# NSS_0_CFG_CPSW register map
Vendor: Texas Instruments
Peripheral module from a debugger description file (folder 66AK2G0x_66AK2G1x).
Registers are 32-bit, access per field, reset 0x0 unless marked. A register's access mark holds for its fields unless they carry their own. Offsets are as the file gives them; lines under a group give offsets from that group; [hi:lo] are bit positions; {n}, {i} and the like mark numbered series; 'fields as' and 'values as' point back to an identical list; <NAME> marks a mode.

## NSS_0_CFG_CPSW
0x00 CPSW_IDVER ro reset 0x4EE71100
  [31:0] REV — TI internal data. Identifies revision of peripheral.
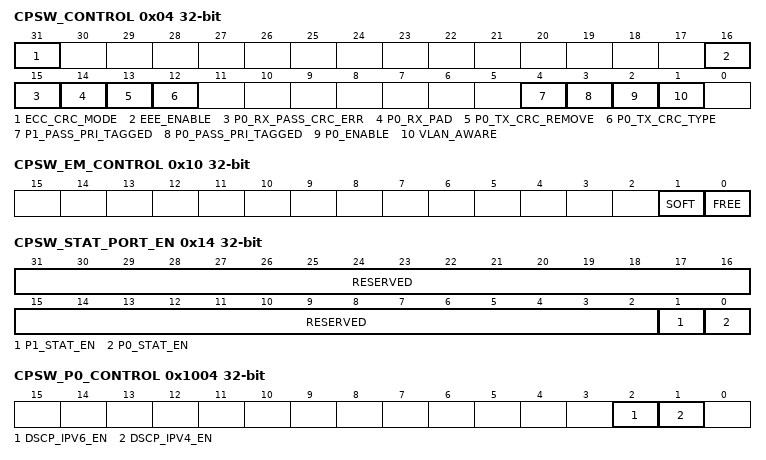
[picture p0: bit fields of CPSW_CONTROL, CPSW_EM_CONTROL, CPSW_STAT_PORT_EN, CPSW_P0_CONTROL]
0x04 CPSW_CONTROL
  [31] ECC_CRC_MODE rw
  [16] EEE_ENABLE rw — Energy Efficient Ethernet enable
  [15] P0_RX_PASS_CRC_ERR rw — Port 0 Pass Received CRC errors
  [14] P0_RX_PAD rw — Port 0 Receive Short Packet Pad
  [13] P0_TX_CRC_REMOVE rw — Port 0 Transmit CRC remove
  [12] P0_TX_CRC_TYPE rw — Port 0 Transmit CRC Type – The type of CRC on all Port 0 transmit packet (egress), regardless of the CRC type of in ingress Ethernet port.
  [4] P1_PASS_PRI_TAGGED rw — Port 1 Pass Priority Tagged
  [3] P0_PASS_PRI_TAGGED rw — Port 0 Pass Priority Tagged
  [2] P0_ENABLE rw — Port 0 Enable
  [1] VLAN_AWARE rw — VLAN Aware Mode
0x10 CPSW_EM_CONTROL
  [1] SOFT rw — Emulation Soft Bit
  [0] FREE rw — Emulation Free Bit
0x14 CPSW_STAT_PORT_EN
  [31:2] RESERVED ro — Reads return 0 and writes have no effect.
  [1] P1_STAT_EN rw — Port 1 Statistics Enable
  [0] P0_STAT_EN rw — Port 0 Statistics Enable
0x1C CPSW_SOFT_IDLE
  [0] SOFT_IDLE rw — Software Idle
0x2C CPSW_EEE_PRESCALE
  [11:0] EEE_PRESCALE rw — Energy Efficient Ethernet Pre-scale count load value - This value is loaded into the EEE pre-scale counter each time the pre-scale count decrements to zero. The EEE counters are enabled to decrement each time the pre-scale counter reaches zero (and the EEE counters are enabled to count time). If this value is zero then the EEE counters decrement on every clock. If this value is 0x001 then the counters decrement on every other clock (and so on).
0x1004 CPSW_P0_CONTROL
  [2] DSCP_IPV6_EN rw — Port 0 IPv6 DSCP enable
  [1] DSCP_IPV4_EN rw — Port 0 IPv4 DSCP enable
0x1008 CPSW_P0_FLOW_ID_OFFSET
  [7:0] FLOW_ID_OFFSET rw — This value is added to the thread/Flow_ID in CPPI transmit PSI Info Word 0
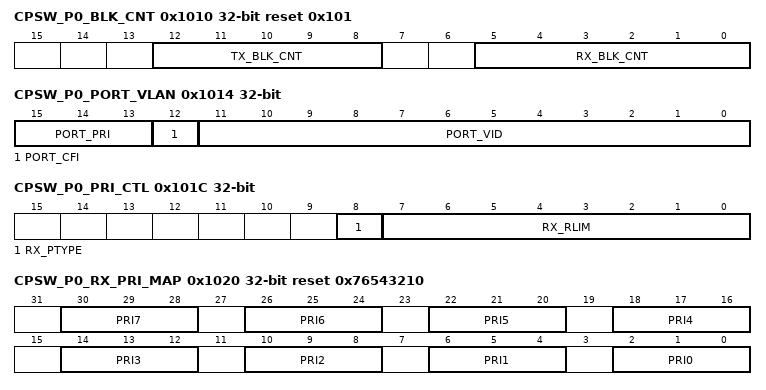
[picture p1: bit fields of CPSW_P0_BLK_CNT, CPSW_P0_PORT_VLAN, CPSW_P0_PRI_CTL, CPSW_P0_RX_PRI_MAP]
0x1010 CPSW_P0_BLK_CNT ro reset 0x101
  [12:8] TX_BLK_CNT — Port 0 Transmit Block Count Usage – This value is the number of blocks allocated to the FIFO logical transmit queues.
  [5:0] RX_BLK_CNT — Port 0 Receive Block Count Usage – This value is the number of blocks allocated in the receive FIFO.
0x1014 CPSW_P0_PORT_VLAN
  [15:13] PORT_PRI rw — Port VLAN Priority
  [12] PORT_CFI rw — Port CFI bit
  [11:0] PORT_VID rw — Port VLAN ID
0x101C CPSW_P0_PRI_CTL
  [8] RX_PTYPE rw — Receive Priority Type
  [7:0] RX_RLIM rw — Receive Rate Limit Enable
0x1020 CPSW_P0_RX_PRI_MAP reset 0x76543210
  [4n+2:4n] PRI{n} rw (n=0..7) — Priority {n} – A packet pri of {0x0+n} is mapped (changed) to this header packet pri.
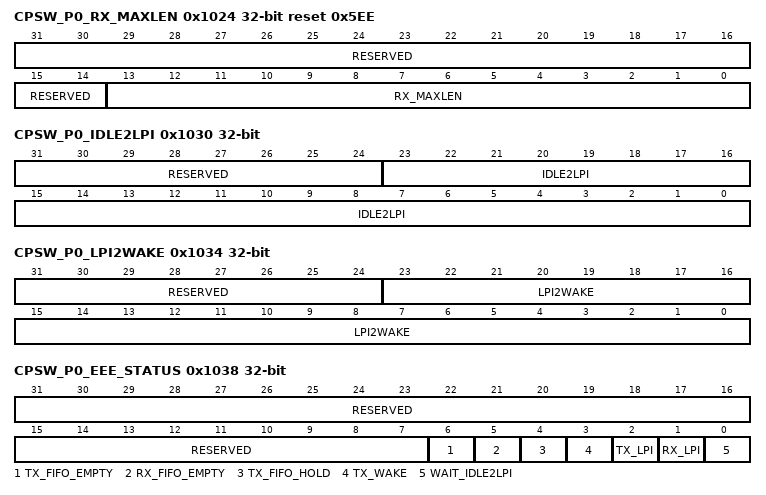
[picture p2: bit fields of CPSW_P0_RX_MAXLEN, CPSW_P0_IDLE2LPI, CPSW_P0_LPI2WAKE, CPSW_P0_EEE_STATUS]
0x1024 CPSW_P0_RX_MAXLEN reset 0x5EE
  [31:14] RESERVED ro — Reads return 0 and writes have no effect.
  [13:0] RX_MAXLEN rw — Rx Maximum Frame Length – This field determines the maximum length of a received frame. The reset value is 1518 (dec). Frames with byte counts greater than RX_MAXLEN are long frames. Long frames with no errors are oversized frames. Long frames with CRC, code, or alignment error are jabber frames. The maximum value is 2020 (including VLAN).
0x1030 CPSW_P0_IDLE2LPI
  [31:24] RESERVED ro — Reads return 0 and writes have no effect.
  [23:0] IDLE2LPI rw — Port 0 EEE Idle to LPI counter load value - After EEE_CLKSTOP_REQ is asserted, this value is loaded into the port 0 idle to LPI counter on each clock that the port 0 transmit or receive is not idle. Port 0 enters the LPI state when this count decrements to zero (on the prescale count). This count value should be large relative to switch operations.
0x1034 CPSW_P0_LPI2WAKE
  [31:24] RESERVED ro — Reads return 0 and writes have no effect.
  [23:0] LPI2WAKE rw — Port 0 EEE LPI to wake counter load value – When the port is in the transmit LPI state and the EEE_CLKSTOP_REQ signal is deasserted, this value is loaded into the port 0 LPI to wake counter. Transmit and receive packet operations may begin (resume) when the LPI to wake count decrements to zero (on the prescale count). This is the time waited before CPPI packet operations begin (resume after wakeup). This count value should be large relative to switch operations.
0x1038 CPSW_P0_EEE_STATUS ro
  [31:7] RESERVED — Reads return 0 and writes have no effect.
  [6] TX_FIFO_EMPTY — CPPI port 0 transmit FIFO (switch egress) is empty - contains no packets
  [5] RX_FIFO_EMPTY — CPPI port 0 receive FIFO (switch ingress) is empty - contains no packets
  [4] TX_FIFO_HOLD — CPPI port 0 transmit FIFO hold - asserted in the LPI state and during the LPI2WAKE count time
  [3] TX_WAKE — CPPI port 0 transmit wakeup - asserted in the transmit LPI2WAKE count time
  [2] TX_LPI — CPPI port 0 transmit LPI state - asserted when the port 0 transmit is in the LPI state
  [1] RX_LPI — CPPI port 0 receive LPI state - asserted when the port 0 receive is in the LPI state
  [0] WAIT_IDLE2LPI — CPPI port 0 wait idle to LPI - asserted when port 0 is counting the IDLE2LPI time
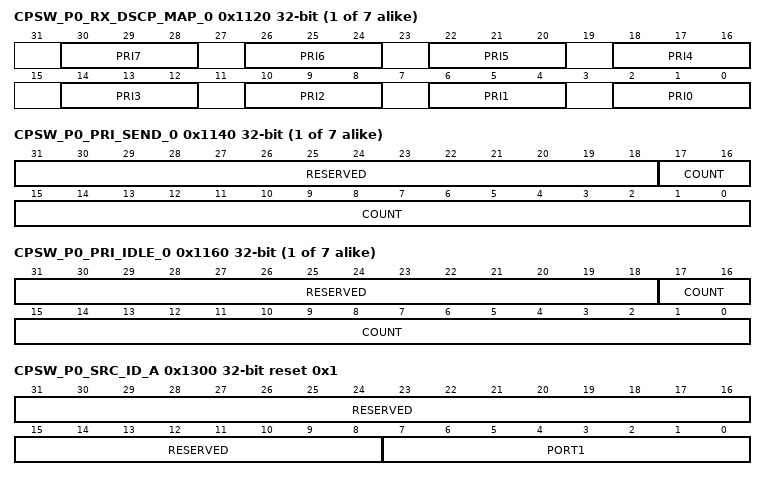
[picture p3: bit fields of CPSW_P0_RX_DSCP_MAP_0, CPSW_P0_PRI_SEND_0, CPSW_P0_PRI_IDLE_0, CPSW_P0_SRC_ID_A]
{0x1120+4i} CPSW_P0_RX_DSCP_MAP_{i} (i=0..6)
  [4n+2:4n] PRI{n} rw (n=0..7) — A DSCP IPV4/V6 packet TOS of N*8+{n} is mapped to this received priority, where N = 0 to 7
{0x1140+4i} CPSW_P0_PRI_SEND_{i} (i=0..6)
  [31:18] RESERVED ro — Reads return 0 and writes have no effect.
  [17:0] COUNT rw — Priority N send count, where N = 0 to 7
{0x1160+4i} CPSW_P0_PRI_IDLE_{i} (i=0..6)
  [31:18] RESERVED ro — Reads return 0 and writes have no effect.
  [17:0] COUNT rw — Priority N idle count, where N = 0 to 7
0x1300 CPSW_P0_SRC_ID_A reset 0x1
  [31:8] RESERVED ro — Reads return 0 and writes have no effect.
  [7:0] PORT1 rw — Port 1 CPPI Info Word0 Source ID Value. This value is contained in the CPPI Info Word 0 src_id field for packets received on port 1.
0x2000 CPSW_P1_RESERVED ro
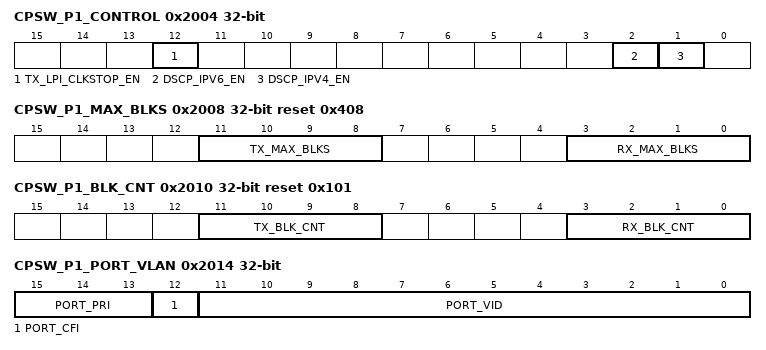
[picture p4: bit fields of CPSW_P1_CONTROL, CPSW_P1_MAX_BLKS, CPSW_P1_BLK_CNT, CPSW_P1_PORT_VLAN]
0x2004 CPSW_P1_CONTROL
  [12] TX_LPI_CLKSTOP_EN rw — Transmit LPI clockstop enable
  [2] DSCP_IPV6_EN rw — IPv6 DSCP enable
  [1] DSCP_IPV4_EN rw — IPv4 DSCP enable
0x2008 CPSW_P1_MAX_BLKS ro reset 0x408
  [11:8] TX_MAX_BLKS — Transmit FIFO maximum blocks - This value is the maximum number of 1k memory blocks that may be allocated to the FIFO’s logical transmit priority queues. The recommended value of TX_MAX_BLKS is 0x4.
  [3:0] RX_MAX_BLKS — Receive FIFO maximum blocks – This value is the maximum number of 1k memory blocks that may be allocated to the FIFO’s logical receive queue. This value must be greater than or equal to 0x3. The recommended value of RX_MAX_BLKS is 0x8.
0x2010 CPSW_P1_BLK_CNT ro reset 0x101
  [11:8] TX_BLK_CNT — Transmit Block Count Usage – This value is the number of blocks allocated to the port’s FIFO logical transmit queues.
  [3:0] RX_BLK_CNT — Receive Block Count Usage – This value is the number of blocks allocated to the port’s FIFO receive queue.
0x2014 CPSW_P1_PORT_VLAN
  [15:13] PORT_PRI rw — Port VLAN Priority (7 is highest priority)
  [12] PORT_CFI rw — Port CFI bit
  [11:0] PORT_VID rw — Port VLAN ID
0x201C CPSW_P1_PRI_CTL reset 0x9000
  [15:12] TX_HOST_BLKS_REM rw — Transmit FIFO Blocks that must be free before a non rate-limited CPPI Port 0 receive thread can begin sending a packet
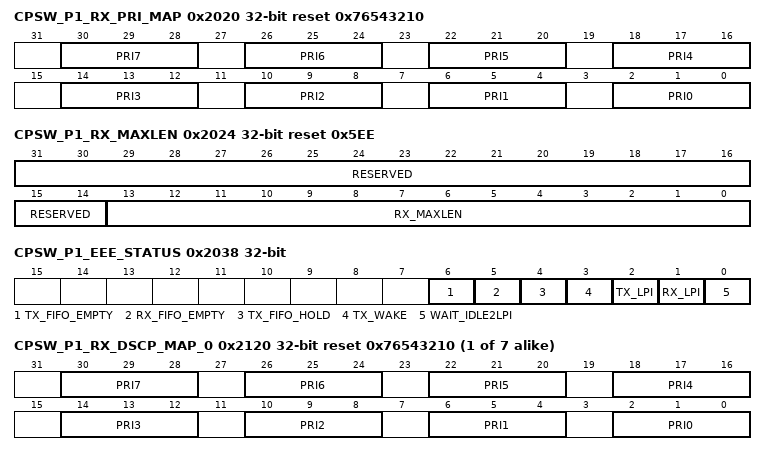
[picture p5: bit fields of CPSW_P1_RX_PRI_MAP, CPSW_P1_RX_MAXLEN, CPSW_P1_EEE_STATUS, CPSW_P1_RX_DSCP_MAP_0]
0x2020 CPSW_P1_RX_PRI_MAP reset 0x76543210
  fields as CPSW_P0_RX_PRI_MAP
0x2024 CPSW_P1_RX_MAXLEN reset 0x5EE
  [31:14] RESERVED ro — Reads return 0 and writes have no effect.
  [13:0] RX_MAXLEN rw — Rx Maximum Frame Length – This field determines the maximum length of a received frame. The reset value is 1518 (dec). Frames with byte counts greater than RX_MAXLEN are long frames. Long frames with no errors are oversized frames. Long frames with CRC, code, or alignment error are jabber frames. The maximum value is 9604 (including VLAN).
0x2030 CPSW_P1_IDLE2LPI
  [23:0] IDLE2LPI rw — EEE Idle to LPI counter load value- After EEE_CLKSTOP_REQ is asserted, this value is loaded into the port idle to LPI counter on each clock that the port transmit is not idle. The port enters the transmit LPI state when this count decrements to zero. This count decrements each time the EEE prescale count decrements to zero.
0x2034 CPSW_P1_LPI2WAKE
  [23:0] LPI2WAKE rw — EEE LPI to wake counter load value – When the port is in the transmit LPI state and the EEE_CLKSTOP_REQ signal is deasserted, this value is loaded into the LPI to wake counter. Transmit packet operations may begin (resume) when the LPI to wake count decrements to zero (on the pre-scale count). This is the time waited before Ethernet transmit operations resume after wakeup.
0x2038 CPSW_P1_EEE_STATUS ro
  [6] TX_FIFO_EMPTY — Transmit FIFO (switch egress) is empty - contains no packets
  [5] RX_FIFO_EMPTY — Receive FIFO (switch ingress) is empty - contains no packets
  [4] TX_FIFO_HOLD — Transmit FIFO hold - asserted in the LPI state and during the LPI2WAKE count time
  [3] TX_WAKE — Transmit wakeup - asserted in the transmit LPI2WAKE count time
  [2] TX_LPI — Transmit LPI state - asserted when the port 0 transmit is in the LPI state
  [1] RX_LPI — Receive LPI state - asserted when the port 0 receive is in the LPI state
  [0] WAIT_IDLE2LPI — CPPI port 0 wait idle to LPI - asserted when port 0 is counting the IDLE2LPI time
{0x2120+4i} CPSW_P1_RX_DSCP_MAP_{i} reset 0x76543210 (i=0..6)
  [4n+2:4n] PRI{n} rw (n=0..7) — A DSCP IPV4/V6 packet TOS of N*8+{n} is mapped to this received priority, where N = 0 to 7.
{0x2140+4i} CPSW_P1_PRI_SEND_{i} (i=0..6)
  [17:0] COUNT rw — Priority N send count, where N = 0 to 7.
{0x2160+4i} CPSW_P1_PRI_IDLE_{i} (i=0..6)
  [17:0] COUNT rw — Priority N idle count, where N = 0 to 7
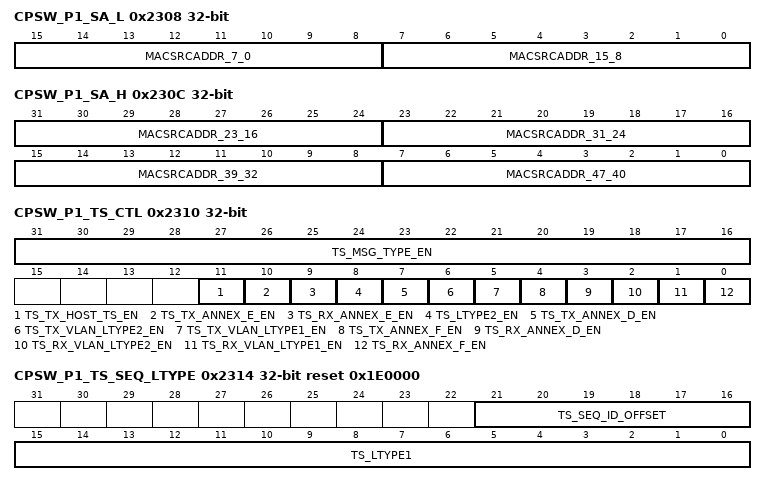
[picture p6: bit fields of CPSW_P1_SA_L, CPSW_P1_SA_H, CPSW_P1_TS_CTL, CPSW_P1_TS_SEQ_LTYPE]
0x2308 CPSW_P1_SA_L
  [15:8] MACSRCADDR_7_0 rw — Source Address Lower 8 bits (byte 0)
  [7:0] MACSRCADDR_15_8 rw — Source Address bits 15:8 (byte 1)
0x230C CPSW_P1_SA_H rw
  [31:24] MACSRCADDR_23_16 — Source Address bits 23:16 (byte 2)
  [23:16] MACSRCADDR_31_24 — Source Address bits 31:24 (byte 3)
  [15:8] MACSRCADDR_39_32 — Source Address bits 39:32 (byte 4)
  [7:0] MACSRCADDR_47_40 — Source Address bits 47:40 (byte 5)
0x2310 CPSW_P1_TS_CTL
  [31:16] TS_MSG_TYPE_EN rw — Time Sync Message Type Enable Each bit in this field enables the corresponding message type in receive and transmit time sync messages (Bit 0 enables message type 0, etc.).
  [11] TS_TX_HOST_TS_EN rw — Time Sync Transmit Host Time Stamp Enable
  [10] TS_TX_ANNEX_E_EN rw — Time Sync Transmit Annex E Enable
  [9] TS_RX_ANNEX_E_EN rw — Time Sync Receive Annex E Enable
  [8] TS_LTYPE2_EN rw — Time Sync LTYPE 2 enable (Transmit and Receive)
  [7] TS_TX_ANNEX_D_EN rw — Time Sync Transmit Annex D Enable
  [6] TS_TX_VLAN_LTYPE2_EN rw — Time Sync Transmit VLAN LTYPE 2 enable
  [5] TS_TX_VLAN_LTYPE1_EN rw — Time Sync Transmit VLAN LTYPE 1 enable
  [4] TS_TX_ANNEX_F_EN rw — Time Sync Transmit Annex F Enable
  [3] TS_RX_ANNEX_D_EN rw — Time Sync Receive Annex D Enable
  [2] TS_RX_VLAN_LTYPE2_EN rw — Time Sync Receive VLAN LTYPE 2 enable
  [1] TS_RX_VLAN_LTYPE1_EN rw — Time Sync Receive VLAN LTYPE 1 enable
  [0] TS_RX_ANNEX_F_EN rw — Time Sync Receive Annex F Enable
0x2314 CPSW_P1_TS_SEQ_LTYPE reset 0x1E0000
  [21:16] TS_SEQ_ID_OFFSET rw — Time Sync Sequence ID Offset. This is the number of octets that the sequence ID is offset in the tx and rx time sync message header. The minimum value is 6.
  [15:0] TS_LTYPE1 rw — Time Sync LTYPE1. This is the port’s time sync LTYPE1 value.
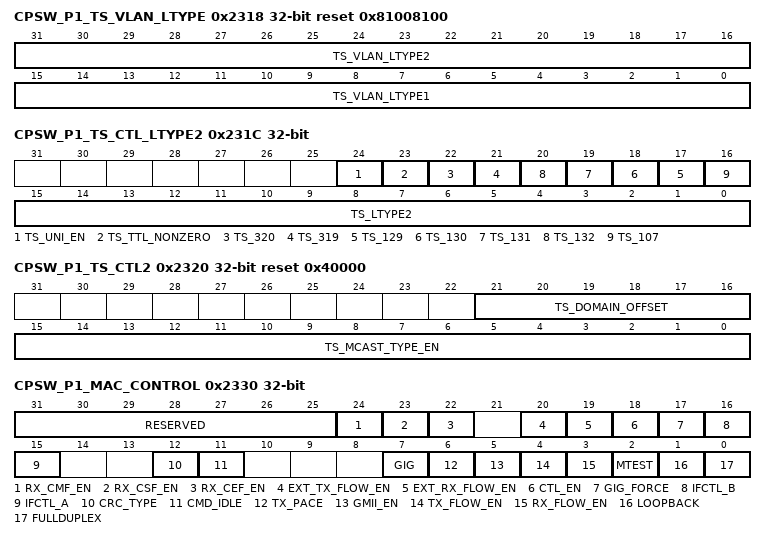
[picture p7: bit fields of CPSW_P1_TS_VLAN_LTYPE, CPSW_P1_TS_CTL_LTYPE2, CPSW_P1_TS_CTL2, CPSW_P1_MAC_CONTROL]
0x2318 CPSW_P1_TS_VLAN_LTYPE rw reset 0x81008100
  [31:16] TS_VLAN_LTYPE2 — Time Sync VLAN LTYPE2. This VLAN LTYPE value is used for the port tx and rx time sync decode.
  [15:0] TS_VLAN_LTYPE1 — Time Sync VLAN LTYPE1. This VLAN LTYPE value is used for the port tx and rx time sync decode.
0x231C CPSW_P1_TS_CTL_LTYPE2
  [24] TS_UNI_EN rw — Time Sync Unicast Enable
  [23] TS_TTL_NONZERO rw — Time Sync Time to Live Non-zero Enable
  [22] TS_320 rw — Time Sync Destination IP Address 320 Enable
  [21] TS_319 rw — Time Sync Destination IP Address 319 Enable
  [n-112] TS_{n} rw (n=129..132) — Time Sync Destination IP Address {n} Enable
  [16] TS_107 rw — Time Sync Destination IP Address 107 Enable
  [15:0] TS_LTYPE2 rw — Time Sync LTYPE2. This is the time sync LTYPE1 value for port 1.
0x2320 CPSW_P1_TS_CTL2 reset 0x40000
  [21:16] TS_DOMAIN_OFFSET rw — Time Sync Domain Offset
  [15:0] TS_MCAST_TYPE_EN rw — Time Sync Multicast Destination Address Type Enable
0x2330 CPSW_P1_MAC_CONTROL
  [31:25] RESERVED ro — Reads return 0 and writes have no effect.
  [24] RX_CMF_EN rw — RX Copy MAC Control Frames Enable – Enables MAC control frames to be transferred to memory. MAC control frames are normally acted upon (if enabled), but not copied to memory. MAC control frames that are pause frames will be acted upon if enabled in the MacControl register, regardless of the value of RX_CMF_EN. Frames transferred to memory due toRX_CMF_EN will have the control bit set in their EOP buffer descriptor.
  [23] RX_CSF_EN rw — Enables frames or fragments shorter than 64 bytes to be copied to memory. Frames transferred to memory due to rx_csf_en will have the fragment or undersized bit set in their receive footer. Fragments are short frames that contain CRC/align/code errors and undersized are short frames without errors.
  [22] RX_CEF_EN rw — RX Copy Error Frames Enable – Enables frames containing errors to be transferred to memory. The appropriate error bit will be set in the frame receive footer. Frames containing errors will be filtered when rx_cef _en is not set.
  [20] EXT_TX_FLOW_EN rw — External Transmit Flow Control Enable Enables the tx_flow_en to be selected from the EXT_TX_FLOW_EN input signal and not from the TX_FLOW_EN bit in this register.
  [19] EXT_RX_FLOW_EN rw — External Receive Flow Control Enable – Enables the rx_flow_en to be selected from the EXT_RX_FLOW_EN input signal and not from the RX_FLOW_EN bit in this register.
  [18] CTL_EN rw — Control Enable – Enables the fullduplex and gigabit mode to be selected from the FULLDUPLEX_IN and GIG_IN input signals and not from the fullduplex and gig bits in this register. The FULLDUPLEX_MODE bit reflects the actual fullduplex mode selected.
  [17] GIG_FORCE rw — Gigabit Mode Force – This bit is used to force the Enet Mac into gigabit mode if the input GMII_MTCLK has been stopped by the PHY.
  [16] IFCTL_B rw — Interface Control B
  [15] IFCTL_A rw — Interface Control A.Determines the RMII speed
  [12] CRC_TYPE rw — Port CRC Type
  [11] CMD_IDLE rw — Command Idle
  [7] GIG rw — Gigabit Mode The GIG_OUT output is the value of this bit.
  [6] TX_PACE rw — Transmit Pacing Enable
  [5] GMII_EN rw — GMII Enable
  [4] TX_FLOW_EN rw — Transmit Flow Control Enable – Determines if incoming pause frames are acted upon in full-duplex mode. Incoming pause frames are not acted upon in half-duplex mode regardless of this bit setting. The RX_MBP_Enable bits determine whether or not received pause frames are transferred to memory.
  [3] RX_FLOW_EN rw — Receive Flow Control Enable
  [2] MTEST rw — Manufacturing Test Mode – This bit must be set to allow writes to the BACKOFF_TEST and PAUSETIMER registers.
  [1] LOOPBACK rw — Loop Back Mode – Loopback mode forces internal fullduplex mode regardless of whether the fullduplex bit is set or not. The loopback bit should be changed only when GMII_EN is de-asserted.
  [0] FULLDUPLEX rw — Full Duplex mode – Gigabit mode forces fullduplex mode regardless of whether the fullduplex bit is set or not. The FULLDUPLEX_OUT output is the value of this register bit
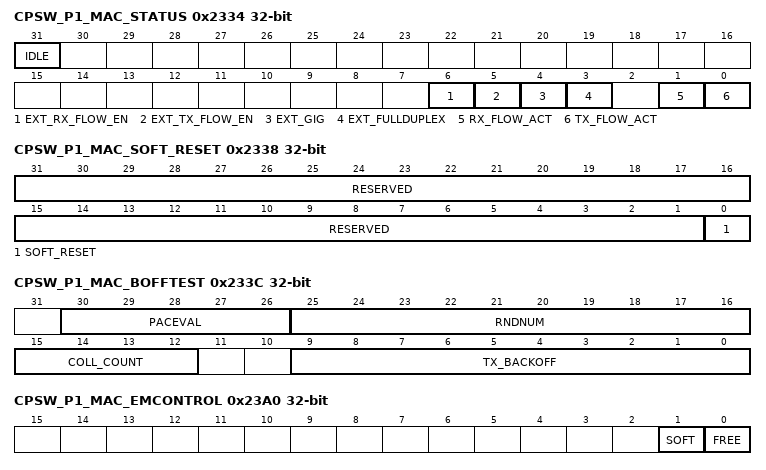
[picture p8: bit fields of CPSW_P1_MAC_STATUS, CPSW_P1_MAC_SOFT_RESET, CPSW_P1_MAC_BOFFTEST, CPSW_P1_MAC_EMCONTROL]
0x2334 CPSW_P1_MAC_STATUS ro (reset mask 0xFFFFFF87)
  [31] IDLE — Enet IDLE – The Ethernet port is in the idle state (valid after an idle command)
  [6] EXT_RX_FLOW_EN — External Receive Flow Control Enable – This is the value of the EXT_RX_FLOW_EN input bit.
  [5] EXT_TX_FLOW_EN — External Receive Flow Control Enable – This is the value of the EXT_TX_FLOW_EN input bit.
  [4] EXT_GIG — External GIG mode – This is the value of the EXT_GIG input bit.
  [3] EXT_FULLDUPLEX — External Fullduplex – This is the value of the EXT_FULLDUPLEX input bit.
  [1] RX_FLOW_ACT — Receive Flow Control Active – When asserted, indicates that receive flow control is enabled and triggered.
  [0] TX_FLOW_ACT — Transmit Flow Control Active When asserted, this bit indicates that the pause time period is being observed for a received pause frame. No new transmissions will begin while this bit is asserted except for the transmission of pause frames. Any transmission in progress when this bit is asserted will complete.
0x2338 CPSW_P1_MAC_SOFT_RESET
  [31:1] RESERVED ro — Reads return 0 and writes have no effect.
  [0] SOFT_RESET rw — Software reset – Writing a one to this bit causes the Ethernet Mac logic to be reset. After writing a one to this bit, it may be polled to determine if the reset has occurred. If a one is read, the reset has not yet occurred. If a zero is read then reset has occurred.
0x233C CPSW_P1_MAC_BOFFTEST
  [30:26] PACEVAL rw — Pacing Register Current Value. A non-zero value in this field indicates that transmit pacing is active. A transmit frame collision or deferral causes paceval to loaded with decimal 31, good frame transmissions (with no collisions or deferrals) cause paceval to be decremented down to zero. When paceval is nonzero, the transmitter delays 4 IPGs between new frame transmissions after each successfully transmitted frame that had no deferrals or collisions. Transmit pacing helps reduce “capture” effects improving overall network bandwidth.
  [25:16] RNDNUM rw — Backoff Random Number Generator – This field allows the Backoff Random Number Generator to be read (or written in test mode only). This field can be written only when mtest has previously been set. Reading this field returns the generator’s current value. The value is reset to zero and begins counting on the clock after the de-assertion of reset
  [15:12] COLL_COUNT ro — Collision Count – The number of collisions the current frame has experienced.
  [9:0] TX_BACKOFF ro — Backoff Count – This field allows the current value of the backoff counter to be observed for test purposes. This field is loaded automatically according to the backoff algorithm, and is decremented by one for each slot time after the collision.
0x2340 CPSW_P1_MAC_RX_PAUSETIMER
  [15:0] RX_PAUSETIMER rw — RX Pause Timer Value – This field allows the contents of the receive pause timer to be observed (and written in test mode). The receive pause timer is loaded with 0xFF00 when the Enet port sends an outgoing pause frame (with pause time of 0xFFFF). The receive pause timer is decremented at slot time intervals. If the receive pause timer decrements to zero, then another outgoing pause frame will be sent and the load/decrement process will be repeated. This register is for 802.3 Based flow control and is not used for 802.1qbb Priority Based Flow Control (PFC).
0x2370 CPSW_P1_MAC_TX_PAUSETIMER
  [15:0] TX_PAUSETIMER rw — 802.3 Tx Pause Timer Value – This field allows the contents of the transmit pause timer to be observed (and written in test mode). The transmit pause timer is loaded by a received (incoming) pause frame, and then decremented, at slottime intervals, down to zero at which time Ethernet Port transmit frames are again enabled. This register is for 802.3 Based flow control and is not used for 802.1qbb Priority Based Flow Control (PFC).
0x23A0 CPSW_P1_MAC_EMCONTROL
  [1] SOFT rw — Emulation Soft Bit
  [0] FREE rw — Emulation Free Bit
0x23A4 CPSW_P1_MAC_TX_GAP reset 0xC
  [15:0] TX_GAP rw — Transmit Inter-Packet Gap This is the default gap value and only bits 8:0 are used. This can be increased from 12 to increase the gap between packets.
